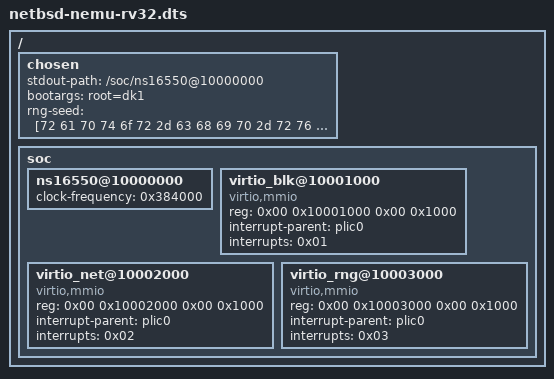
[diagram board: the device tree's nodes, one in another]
/*
 * NetBSD netboot device tree for the NEMU / RTL-sim platform (RV32).
 *
 * See netbsd-nemu-rv64.dts for the rationale.  RV32 NetBSD GENERIC is an
 * ilp32d (double-float ABI) kernel, so spike-rv32gc.dts is used as the base to
 * advertise the F/D extensions the kernel was compiled against.
 */
/include/ "spike-rv32gc.dts"

/ {
	chosen {
		stdout-path = "/soc/ns16550@10000000";
		bootargs = "root=dk1";
		rng-seed = [72 61 70 74 6f 72 2d 63 68 69 70 2d 72 76 33 32
		            2d 6e 65 74 62 73 64 2d 6e 65 6d 75 2d 73 65 65
		            64 2d 64 65 74 65 72 6d 69 6e 69 73 74 69 63 21];
	};

	soc {
		ns16550@10000000 {
			clock-frequency = <0x384000>;
		};

		virtio_blk@10001000 {
			compatible = "virtio,mmio";
			reg = <0x00 0x10001000 0x00 0x1000>;
			interrupt-parent = <&plic0>;
			interrupts = <0x01>;
		};

		virtio_net@10002000 {
			compatible = "virtio,mmio";
			reg = <0x00 0x10002000 0x00 0x1000>;
			interrupt-parent = <&plic0>;
			interrupts = <0x02>;
		};

		virtio_rng@10003000 {
			compatible = "virtio,mmio";
			reg = <0x00 0x10003000 0x00 0x1000>;
			interrupt-parent = <&plic0>;
			interrupts = <0x03>;
		};
	};
};
